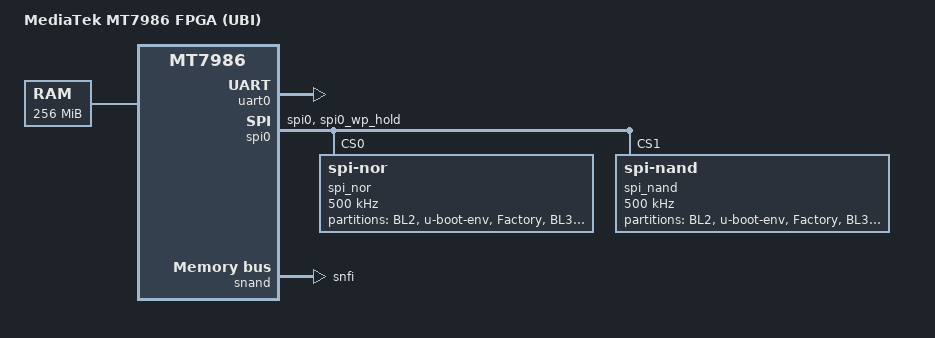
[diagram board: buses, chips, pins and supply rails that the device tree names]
/dts-v1/;
#include "mt7986-fpga.dtsi"
/ {
	model = "MediaTek MT7986 FPGA (UBI)";
	compatible = "mediatek,mt7986-fpga,ubi";
	chosen {
		bootargs = "console=ttyS0,115200n1 loglevel=8  \
				earlycon=uart8250,mmio32,0x11002000";
	};

	memory {
		// fpga ddr2: 128MB*2
		reg = <0 0x40000000 0 0x10000000>;
	};
};

&uart0 {
	status = "okay";
};

&spi0 {
	pinctrl-names = "default";
	pinctrl-0 = <&spi_flash_pins>;
	status = "okay";
	spi_nor@0 {
		#address-cells = <1>;
		#size-cells = <1>;
		compatible = "jedec,spi-nor";
		reg = <0>;
		spi-max-frequency = <500000>;

		partition@00000 {
			label = "BL2";
			reg = <0x00000 0x0060000>;
		};
		partition@60000 {
			label = "u-boot-env";
			reg = <0x60000 0x0010000>;
		};
		partition@70000 {
			label = "Factory";
			reg = <0x70000 0x00B0000>;
		};
		partition@120000 {
			label = "BL31";
			reg = <0x120000 0x0010000>;
		};
		partition@130000 {
			label = "u-boot";
			reg = <0x130000 0x00D0000>;
		};
		partition@200000 {
			label = "firmware";
			reg = <0x200000 0xE00000>;
		};
	};
	spi_nand@1 {
		#address-cells = <1>;
		#size-cells = <1>;
		compatible = "spi-nand";
		reg = <1>;
		spi-max-frequency = <500000>;

		partition@00000 {
			label = "BL2";
			reg = <0x00000 0x0100000>;
		};
		partition@100000 {
			label = "u-boot-env";
			reg = <0x100000 0x0080000>;
		};
		partition@180000 {
			label = "Factory";
			reg = <0x180000 0x00200000>;
		};
		partition@380000 {
			label = "BL31";
			reg = <0x380000 0x0080000>;
		};
		partition@400000 {
			label = "u-boot";
			reg = <0x400000 0x0180000>;
		};
		partition@580000 {
			label = "firmware";
			reg = <0x580000 0x7a80000>;
		};
	};
};

&spi1 {
	pinctrl-names = "default";
	/* pin shared with snfi */
	pinctrl-0 = <&spic_pins>;
	status = "disabled";
};

&pio {
	spi_flash_pins: spi0-pins {
		mux {
			function = "flash";
			groups = "spi0", "spi0_wp_hold";
		};
	};

	snfi_pins: snfi-pins {
		mux {
			function = "flash";
			groups = "snfi";
		};
	};

	spic_pins: spi1-pins {
		mux {
			function = "spi";
			groups = "spi1_1";
		};
	};
};

&watchdog {
	status = "disabled";
};

&snand {
	pinctrl-names = "default";
	/* pin shared with spic */
	pinctrl-0 = <&snfi_pins>;
	status = "okay";
	mediatek,quad-spi;

	partitions {
		compatible = "fixed-partitions";
		#address-cells = <1>;
		#size-cells = <1>;

		partition@0 {
			label = "BL2";
			reg = <0x00000 0x0100000>;
			read-only;
		};

		partition@100000 {
			label = "u-boot-env";
			reg = <0x0100000 0x0080000>;
		};

		partition@180000 {
			label = "Factory";
			reg = <0x180000 0x0200000>;
		};

		partition@380000 {
			label = "FIP";
			reg = <0x380000 0x0200000>;
		};

		partition@580000 {
			label = "ubi";
			reg = <0x580000 0x4000000>;
		};
	};
};
